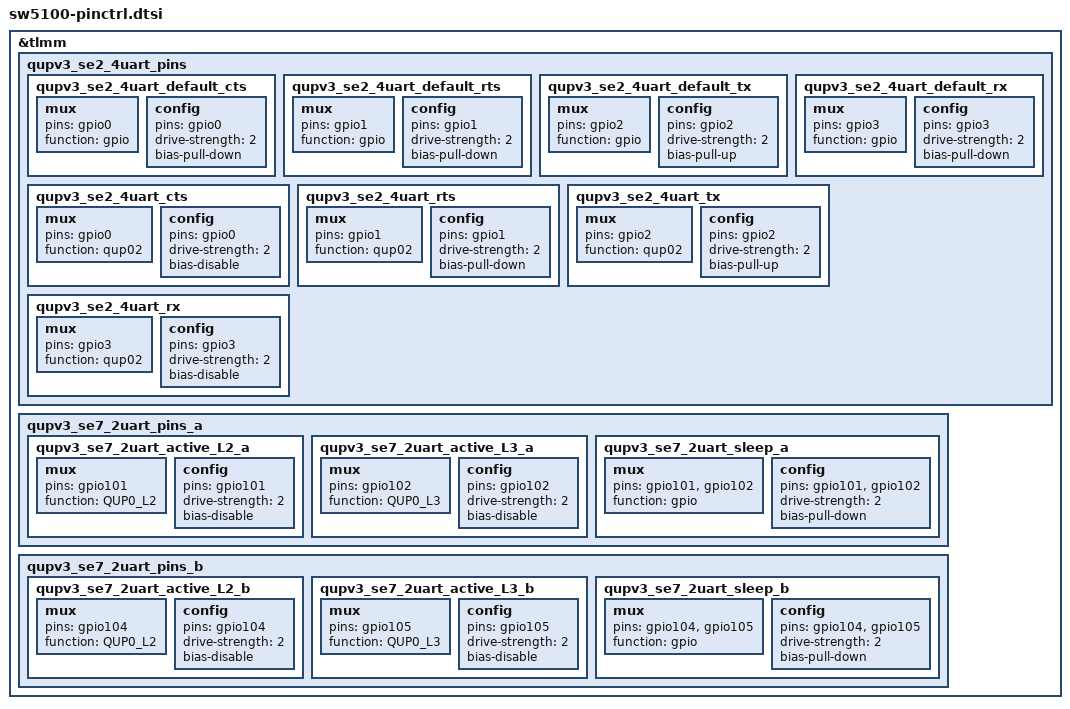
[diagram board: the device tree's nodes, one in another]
// SPDX-License-Identifier: GPL-2.0

&tlmm {
	qupv3_se2_4uart_pins: qupv3_se2_4uart_pins {
		qupv3_se2_4uart_default_cts: qupv3_se2_4uart_default_cts {
			mux {
				pins = "gpio0";
				function = "gpio";
			};

			config {
				pins = "gpio0";
				drive-strength = <2>;
				bias-pull-down;
			};
		};

		qupv3_se2_4uart_default_rts: qupv3_se2_4uart_default_rts {
			mux {
				pins = "gpio1";
				function = "gpio";
			};

			config {
				pins = "gpio1";
				drive-strength = <2>;
				bias-pull-down;
			};
		};

		qupv3_se2_4uart_default_tx: qupv3_se2_4uart_default_tx {
			mux {
				pins = "gpio2";
				function = "gpio";
			};

			config {
				pins = "gpio2";
				drive-strength = <2>;
				bias-pull-up;
			};
		};

		qupv3_se2_4uart_default_rx: qupv3_se2_4uart_default_rx {
			mux {
				pins = "gpio3";
				function = "gpio";
			};

			config {
				pins = "gpio3";
				drive-strength = <2>;
				bias-pull-down;
			};
		};

		qupv3_se2_4uart_cts: qupv3_se2_4uart_cts {
			mux {
				pins = "gpio0";
				function = "qup02";
			};

			config {
				pins = "gpio0";
				drive-strength = <2>;
				bias-disable;
			};
		};

		qupv3_se2_4uart_rts: qupv3_se2_4uart_rts {
			mux {
				pins = "gpio1";
				function = "qup02";
			};

			config {
				pins = "gpio1";
				drive-strength = <2>;
				bias-pull-down;
			};
		};

		qupv3_se2_4uart_tx: qupv3_se2_4uart_tx {
			mux {
				pins = "gpio2";
				function = "qup02";
			};

			config {
				pins = "gpio2";
				drive-strength = <2>;
				bias-pull-up;
			};
		};

		qupv3_se2_4uart_rx: qupv3_se2_4uart_rx {
			mux {
				pins = "gpio3";
				function = "qup02";
			};

			config {
				pins = "gpio3";
				drive-strength = <2>;
				bias-disable;
			};
		};
	};

	qupv3_se7_2uart_pins_a: qupv3_se7_2uart_pins_a {
		qupv3_se7_2uart_active_L2_a: qupv3_se7_2uart_active_L2_a {
			mux {
				pins = "gpio101";
				function = "QUP0_L2";
			};

			config {
				pins = "gpio101";
				drive-strength = <2>;
				bias-disable;
			};
		};

		qupv3_se7_2uart_active_L3_a: qupv3_se7_2uart_active_L3_a {
			mux {
				pins = "gpio102";
				function = "QUP0_L3";
			};

			config {
				pins = "gpio102";
				drive-strength = <2>;
				bias-disable;
			};
		};

		qupv3_se7_2uart_sleep_a: qupv3_se7_2uart_sleep_a {
			mux {
				pins = "gpio101", "gpio102";
				function = "gpio";
			};

			config {
				pins = "gpio101", "gpio102";
				drive-strength = <2>;
				bias-pull-down;
			};
		};
	};

	qupv3_se7_2uart_pins_b: qupv3_se7_2uart_pins_b {
		qupv3_se7_2uart_active_L2_b: qupv3_se7_2uart_active_L2_b {
			mux {
				pins = "gpio104";
				function = "QUP0_L2";
			};

			config {
				pins = "gpio104";
				drive-strength = <2>;
				bias-disable;
			};
		};

		qupv3_se7_2uart_active_L3_b: qupv3_se7_2uart_active_L3_b {
			mux {
				pins = "gpio105";
				function = "QUP0_L3";
			};

			config {
				pins = "gpio105";
				drive-strength = <2>;
				bias-disable;
			};
		};

		qupv3_se7_2uart_sleep_b: qupv3_se7_2uart_sleep_b {
			mux {
				pins = "gpio104", "gpio105";
				function = "gpio";
			};

			config {
				pins = "gpio104", "gpio105";
				drive-strength = <2>;
				bias-pull-down;
			};
		};
	};
};
